# CY8C4247AZI_M485 register map
File version: 0.1
PSoC 4200M
Registers are 32-bit, read-write, no defined reset value unless marked. A register's access mark holds for its fields unless they carry their own. Offsets are from the block's base; lines under a group give offsets from that group; [hi:lo] are bit positions; {n}, {i} and the like mark numbered series; 'fields as' and 'values as' point back to an identical list; <NAME> marks a mode.

## Memory map
0x00000000 ResetTimer
0x00000000 adc — Sequencing SAR ADC
0x00000000 PWM
0x00000000 CapSense_IDAC1 — IDAC
0x00000000 CapSense_IDAC2 — IDAC
0x00000000 EZI2C — Serial Communication Block
0x00000000 BLEIOT_UART — Serial Communication Block
0x00000000 LCD
0x40000000 DMAC — DMAC Registers

## ResetTimer
Base 0x00000000
0x40200108 COUNTER — Current counter value
0x4020010C CC — Compare / capture value
0x40200110 CC_BUF — Compare / capture buffer value
0x40200114 PERIOD — Period value
0x40200118 PERIOD_BUF — Period buffer value

## PWM
Base 0x00000000
0x40200248 COUNTER — Current counter value
0x4020024C CC — Compare / capture value
0x40200250 CC_BUF — Compare / capture buffer value
0x40200254 PERIOD — Period value
0x40200258 PERIOD_BUF — Period buffer value

## CapSense_IDAC1 — IDAC
Base 0x00000000
Same registers: CapSense_IDAC2 0x00000000
0x40280004 CSD_IDAC_POLARITY
0x40280008 CSD_IDAC
0x4028FF00 CSD_TRIM1 — CSD IDAC TRIM1
0x4028FF04 CSD_TRIM2 — CSD IDAC TRIM2

## LCD
Base 0x00000000
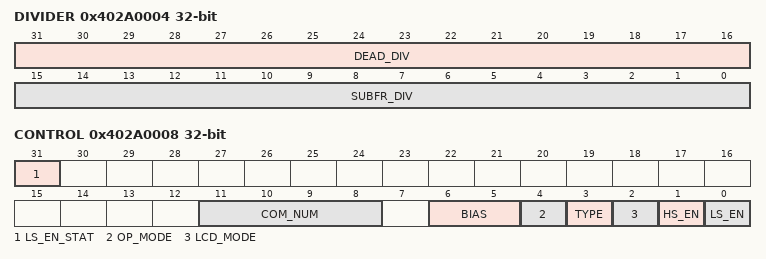
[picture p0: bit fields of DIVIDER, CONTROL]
0x402A0004 DIVIDER — The bits in LCD_DIV_CONFIG are used to configure both HS generator and LS generator. Note that the LS generator will use only the lower 8 bits of each fields and ignore the upper 8.
  [31:16] DEAD_DIV — Length of the dead time period in cycles. When set to zero, no dead time period exists.
  [15:0] SUBFR_DIV — Input clock frequency divide value, to generate the 1/4 sub-frame period. The sub-frame period is 4*(SUBFR_DIV+1) cycles long.
0x402A0008 CONTROL — The same bits in LCD_CONTROL are used to configure both HS generator and LS generator.
  [31] LS_EN_STAT ro — LS enable status bit.
  [11:8] COM_NUM — The number of COM connections minus 2.
  [6:5] BIAS — PWM bias selection
    0=HALF (1/2 Bias); 1=THIRD (1/3 Bias)
  [4] OP_MODE — Driving mode configuration
    0=PWM (PWM Mode); 1=CORRELATION (Digital Correlation Mode)
  [3] TYPE — LCD driving waveform type configuration.
    0=TYPE_A (Each frame addresses each COM pin only once with a balanced (DC=0) waveform.); 1=TYPE_B (Each frame addresses each COM pin twice in sequence with a positive and negative waveform that together are balanced (DC=0).)
  [2] LCD_MODE — HS/LS Mode selection
    0=LS (Select Low Speed (32kHz) Generator (Works in Active and DeepSleep power modes).); 1=HS (Select High Speed (system clock) Generator (Works in Active power mode only).)
  [1] HS_EN — High speed (HS) generator enable
    0=disable (High speed (HS) generator disable); 1=enable (High speed (HS) generator enable)
  [0] LS_EN — Low speed (LS) generator enable
    0=disable (Low speed (LS) generator disable); 1=enable (Low speed (LS) generator enable)
{0x402A0100+4i} DATA{i:02} (i=0..4) — Pin data for COM1..COM4 for port {i}.
  [31:0] DATA — Bits [4i+3:4i] represent the pin data for pin [i] for COMS 1-4 (COM1 is lsb).
